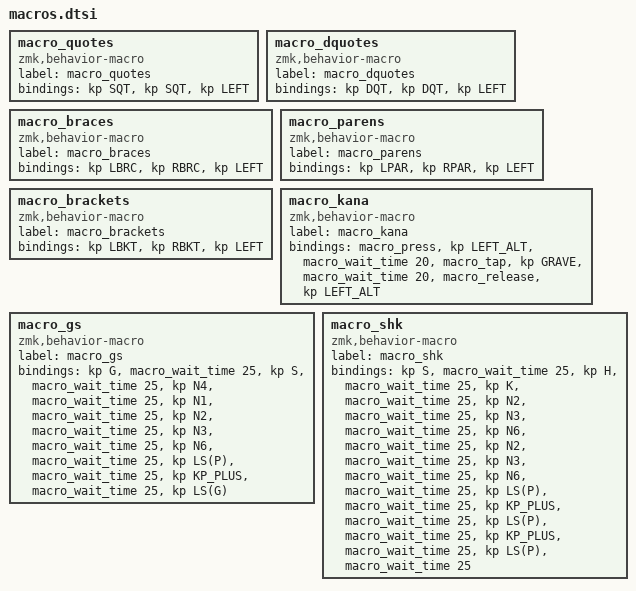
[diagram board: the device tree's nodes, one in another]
macro_quotes: macro_quotes{
compatible = "zmk,behavior-macro";
label = "macro_quotes";
#binding-cells = <0>;
bindings = <&kp SQT>, <&kp SQT>, <&kp LEFT>;
};
macro_dquotes: macro_dquotes{
compatible = "zmk,behavior-macro";
label = "macro_dquotes";
#binding-cells = <0>;
bindings = <&kp DQT>, <&kp DQT>, <&kp LEFT>;
};
macro_braces: macro_braces{
compatible = "zmk,behavior-macro";
label = "macro_braces";
#binding-cells = <0>;
bindings = <&kp LBRC>, <&kp RBRC>, <&kp LEFT>;
};
macro_parens: macro_parens{
compatible = "zmk,behavior-macro";
label = "macro_parens";
#binding-cells = <0>;
bindings = <&kp LPAR>, <&kp RPAR>, <&kp LEFT>;
};
macro_brackets: macro_brackets{
compatible = "zmk,behavior-macro";
label = "macro_brackets";
#binding-cells = <0>;
bindings = <&kp LBKT>, <&kp RBKT>, <&kp LEFT>;
};
macro_kana: macro_kana{
compatible = "zmk,behavior-macro";
label = "macro_kana";
#binding-cells = <0>;
bindings = <&macro_press &kp LEFT_ALT>, <&macro_wait_time 20>, <&macro_tap &kp GRAVE>, <&macro_wait_time 20>, <&macro_release &kp LEFT_ALT>;
};
macro_gs: macro_gs{
compatible = "zmk,behavior-macro";
label = "macro_gs";
#binding-cells = <0>;
bindings = <&kp G>, <&macro_wait_time 25>, <&kp S>, <&macro_wait_time 25>, <&kp N4>, <&macro_wait_time 25>, <&kp N1>, <&macro_wait_time 25>, <&kp N2>, <&macro_wait_time 25>, <&kp N3>, <&macro_wait_time 25>, <&kp N6>, <&macro_wait_time 25>, <&kp LS(P)>, <&macro_wait_time 25>, <&kp KP_PLUS>, <&macro_wait_time 25>, <&kp LS(G)>;
};
macro_shk: macro_shk{
compatible = "zmk,behavior-macro";
label = "macro_shk";
#binding-cells = <0>;
bindings = <&kp S>, <&macro_wait_time 25>, <&kp H>, <&macro_wait_time 25>, <&kp K>, <&macro_wait_time 25>, <&kp N2>, <&macro_wait_time 25>, <&kp N3>, <&macro_wait_time 25>, <&kp N6>, <&macro_wait_time 25>, <&kp N2>, <&macro_wait_time 25>, <&kp N3>, <&macro_wait_time 25>, <&kp N6>, <&macro_wait_time 25>, <&kp LS(P)>, <&macro_wait_time 25>, <&kp KP_PLUS>, <&macro_wait_time 25>, <&kp LS(P)>, <&macro_wait_time 25>, <&kp KP_PLUS>, <&macro_wait_time 25>, <&kp LS(P)>, <&macro_wait_time 25>;
};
